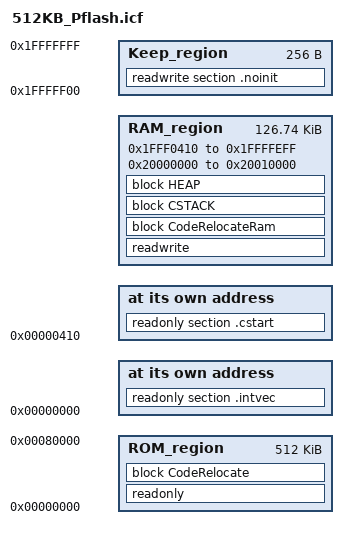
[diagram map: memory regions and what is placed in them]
/*###ICF### Section handled by ICF editor, don't touch! ****/
/*-Editor annotation file-*/
/* IcfEditorFile="$TOOLKIT_DIR$\config\ide\IcfEditor\cortex_v1_0.xml" */
/*-Specials-*/
define symbol __ICFEDIT_intvec_start__ = 0x00000000;
/*-Memory Regions-*/
define symbol __ICFEDIT_region_ROM_start__ = 0x00000000;
define symbol __ICFEDIT_region_ROM_end__   = 0x00080000;
define symbol __ICFEDIT_region_RAM_start__ = 0x1FFF0410;
define symbol __ICFEDIT_region_RAM_end__   = 0x1FFFFEFF;

define symbol __Sword_Keep_Start = 0x1FFFFF00;  /* 256byte不被初始化的区域 */
define symbol __Sword_Keep_End   = 0x1FFFFFFF;
/*-Sizes-*/
define symbol __ICFEDIT_size_cstack__ = 0x1000;
define symbol __ICFEDIT_size_heap__   = 0x200;
/**** End of ICF editor section. ###ICF###*/

define symbol __region_RAM2_start__ = 0x20000000;
define symbol __region_RAM2_end__ = 0x20010000;

define exported symbol __VECTOR_TABLE   = 0x00000000;
define exported symbol __RAM_Vector__ = 0x1fff0000;

define exported symbol __SP_INIT = __region_RAM2_end__ - 8;	//0x2000FFF8;

define symbol __code_start__ = 0x00000410;

define memory mem with size = 4G;
define region ROM_region   = mem:[from __ICFEDIT_region_ROM_start__   to __ICFEDIT_region_ROM_end__];
define region RAM_region   = mem:[from __ICFEDIT_region_RAM_start__   to __ICFEDIT_region_RAM_end__] | mem:[from __region_RAM2_start__ to __region_RAM2_end__];

/* 非初始化内存区域的范围 */
define region Keep_region  = mem:[from __Sword_Keep_Start  to  __Sword_Keep_End];

define block CSTACK    with alignment = 8, size = __ICFEDIT_size_cstack__   { };
define block HEAP      with alignment = 8, size = __ICFEDIT_size_heap__     { };

initialize manually { readwrite };
initialize manually { section .data};
initialize manually { section .textrw };
do not initialize  { section .noinit };
do not initialize  { section .cstart };

define block CodeRelocate { section .textrw_init };
define block CodeRelocateRam { section .textrw };


place at address mem:__ICFEDIT_intvec_start__ { readonly section .intvec }; /* 中断向量表 */
place at address mem:__code_start__ { readonly section .cstart };           /* 启动代码 */

place in Keep_region  { readwrite section .noinit };                        /* 非初始化内存 */

place in ROM_region   { readonly, block CodeRelocate};

place in RAM_region   { readwrite, block CodeRelocateRam,
                        block CSTACK, block HEAP };
 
